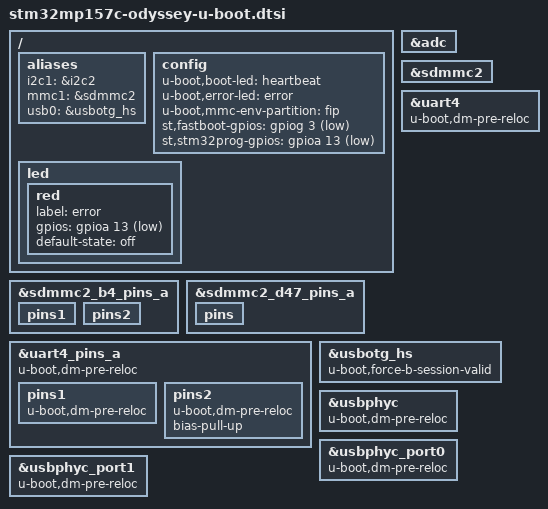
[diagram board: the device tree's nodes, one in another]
// SPDX-License-Identifier: GPL-2.0+ OR BSD-3-Clause
/*
 * Copyright (C) 2020 Marcin Sloniewski <marcin.sloniewski@gmail.com>
 */

#include "stm32mp157c-odyssey-som-u-boot.dtsi"

/ {
	aliases {
        i2c1 = &i2c2;
		mmc1 = &sdmmc2;
		usb0 = &usbotg_hs;
	};

	config {
        u-boot,boot-led = "heartbeat";
		u-boot,error-led = "error";
        u-boot,mmc-env-partition = "fip";
		st,fastboot-gpios = <&gpiog 3 GPIO_ACTIVE_LOW>;
		st,stm32prog-gpios = <&gpioa 13 GPIO_ACTIVE_LOW>;
	};

	led {
		red {
			label = "error";
			gpios = <&gpioa 13 GPIO_ACTIVE_LOW>;
			default-state = "off";
			status = "okay";
		};
	};
};

&adc {
	status = "okay";
};

&sdmmc2 {
	u-boot,dm-spl;
};

&sdmmc2_b4_pins_a {
	u-boot,dm-spl;
	pins1 {
		u-boot,dm-spl;
	};
	pins2 {
		u-boot,dm-spl;
	};
};

&sdmmc2_d47_pins_a {
	u-boot,dm-spl;
	pins {
		u-boot,dm-spl;
	};
};

&uart4 {
	u-boot,dm-pre-reloc;
};

&uart4_pins_a {
	u-boot,dm-pre-reloc;
	pins1 {
		u-boot,dm-pre-reloc;
	};
	pins2 {
		u-boot,dm-pre-reloc;
        bias-pull-up;
	};
};

&usbotg_hs {                   
    u-boot,force-b-session-valid;  
};

&usbphyc {
	u-boot,dm-pre-reloc;
};

&usbphyc_port0 {
	u-boot,dm-pre-reloc;
};

&usbphyc_port1 {
	u-boot,dm-pre-reloc;
};

